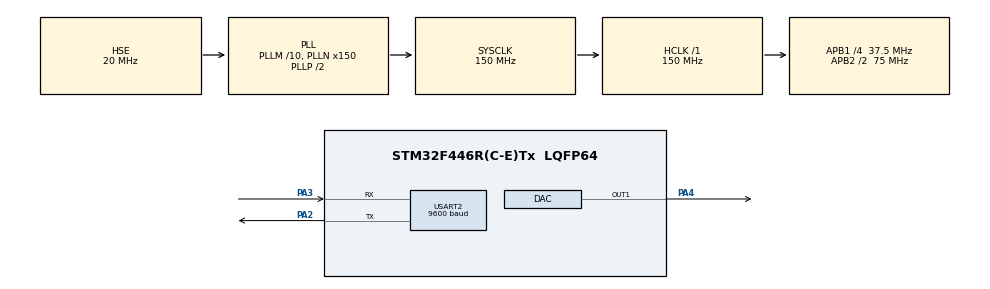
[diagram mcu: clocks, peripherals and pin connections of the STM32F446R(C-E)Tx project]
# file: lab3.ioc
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Mcu.Family=STM32F4
Mcu.Name=STM32F446R(C-E)Tx
Mcu.Package=LQFP64
NVIC.PriorityGroup=NVIC_PRIORITYGROUP_4
NVIC.TIM1_UP_TIM10_IRQn=true\:0\:0\:false\:false\:true\:true\:true\:true
NVIC.USART2_IRQn=true\:0\:0\:false\:false\:true\:true\:true\:true
PA2.Mode=Asynchronous
PA2.Signal=USART2_TX
PA3.Mode=Asynchronous
PA3.Signal=USART2_RX
PA4.Signal=COMP_DAC1_group
PH0-OSC_IN.Mode=HSE-External-Oscillator
PH0-OSC_IN.Signal=RCC_OSC_IN
PH1-OSC_OUT.Mode=HSE-External-Oscillator
PH1-OSC_OUT.Signal=RCC_OSC_OUT
ProjectManager.HeapSize=0x200
ProjectManager.StackSize=0x400
ProjectManager.TargetToolchain=STM32CubeIDE
RCC.AHBFreq_Value=150000000
RCC.APB1CLKDivider=RCC_HCLK_DIV4
RCC.APB1Freq_Value=37500000
RCC.APB1TimFreq_Value=75000000
RCC.APB2CLKDivider=RCC_HCLK_DIV2
RCC.APB2Freq_Value=75000000
RCC.APB2TimFreq_Value=150000000
RCC.CortexFreq_Value=150000000
RCC.HCLKFreq_Value=150000000
RCC.HSE_VALUE=20000000
RCC.PLLM=10
RCC.PLLN=150
RCC.PLLSourceVirtual=RCC_PLLSOURCE_HSE
RCC.SYSCLKFreq_VALUE=150000000
RCC.SYSCLKSource=RCC_SYSCLKSOURCE_PLLCLK
RCC.USBFreq_Value=150000000
RCC.VCOOutputFreq_Value=300000000
SH.COMP_DAC1_group.0=DAC_OUT1,DAC_OUT1
TIM1.Period=999
TIM1.Prescaler=149
TIM1.TIM_MasterOutputTrigger=TIM_TRGO_UPDATE
USART2.BaudRate=9600
USART2.VirtualMode=VM_ASYNC
VP_TIM1_VS_ClockSourceINT.Mode=Internal
board=custom

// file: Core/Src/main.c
/* USER CODE BEGIN Header */
/**
  ******************************************************************************
  * @file           : main.c
  * @brief          : Main program body
  ******************************************************************************
  * @attention
  *
  * Copyright (c) 2024 STMicroelectronics.
  * All rights reserved.
  *
  * This software is licensed under terms that can be found in the LICENSE file
  * in the root directory of this software component.
  * If no LICENSE file comes with this software, it is provided AS-IS.
  *
  ******************************************************************************
  */
/* USER CODE END Header */
#include "main.h"

/* USER CODE BEGIN Includes */
#include <math.h>
#include <string.h>
#include <stdio.h>
/* USER CODE END Includes */

/* USER CODE BEGIN PD */
#define SAMPLE_RATE 1000
#define VREF 3.3

#define UART_BUFFER_SIZE 5
/* USER CODE END PD */

DAC_HandleTypeDef hdac;

TIM_HandleTypeDef htim1;

UART_HandleTypeDef huart2;

/* USER CODE BEGIN PV */
float frequency = 30.0;
float amplitude_volts = 1.5;
float phase = 0.0;

volatile uint32_t dac_value;
volatile float dac_output_voltage;

uint8_t rx_buffer[UART_BUFFER_SIZE];
/* USER CODE END PV */

void SystemClock_Config(void);
static void MX_GPIO_Init(void);
static void MX_DAC_Init(void);
static void MX_TIM1_Init(void);
static void MX_USART2_UART_Init(void);
/* USER CODE BEGIN PFP */
void update_sine_wave(void);
uint32_t calculate_dac_value(float sine_voltage);
/* USER CODE END PFP */

int main(void)
{

  /* MCU Configuration--------------------------------------------------------*/

  /* Reset of all peripherals, Initializes the Flash interface and the Systick. */
  HAL_Init();

  /* Configure the system clock */
  SystemClock_Config();

  /* Initialize all configured peripherals */
  MX_GPIO_Init();
  MX_DAC_Init();
  MX_TIM1_Init();
  MX_USART2_UART_Init();
  /* USER CODE BEGIN 2 */
  HAL_UART_Receive_IT(&huart2, rx_buffer, UART_BUFFER_SIZE);
  HAL_DAC_Start(&hdac, DAC_CHANNEL_1);

  /* USER CODE END 2 */

  /* Infinite loop */
  while (1)
  {

  }
}

void SystemClock_Config(void)
{
  RCC_OscInitTypeDef RCC_OscInitStruct = {0};
  RCC_ClkInitTypeDef RCC_ClkInitStruct = {0};

  /** Configure the main internal regulator output voltage
  */
  __HAL_RCC_PWR_CLK_ENABLE();
  __HAL_PWR_VOLTAGESCALING_CONFIG(PWR_REGULATOR_VOLTAGE_SCALE1);

  /** Initializes the RCC Oscillators according to the specified parameters
  * in the RCC_OscInitTypeDef structure.
  */
  RCC_OscInitStruct.OscillatorType = RCC_OSCILLATORTYPE_HSE;
  RCC_OscInitStruct.HSEState = RCC_HSE_ON;
  RCC_OscInitStruct.PLL.PLLState = RCC_PLL_ON;
  RCC_OscInitStruct.PLL.PLLSource = RCC_PLLSOURCE_HSE;
  RCC_OscInitStruct.PLL.PLLM = 10;
  RCC_OscInitStruct.PLL.PLLN = 150;
  RCC_OscInitStruct.PLL.PLLP = RCC_PLLP_DIV2;
  RCC_OscInitStruct.PLL.PLLQ = 2;
  RCC_OscInitStruct.PLL.PLLR = 2;
  if (HAL_RCC_OscConfig(&RCC_OscInitStruct) != HAL_OK)
  {
    Error_Handler();
  }

  /** Initializes the CPU, AHB and APB buses clocks
  */
  RCC_ClkInitStruct.ClockType = RCC_CLOCKTYPE_HCLK|RCC_CLOCKTYPE_SYSCLK
                              |RCC_CLOCKTYPE_PCLK1|RCC_CLOCKTYPE_PCLK2;
  RCC_ClkInitStruct.SYSCLKSource = RCC_SYSCLKSOURCE_PLLCLK;
  RCC_ClkInitStruct.AHBCLKDivider = RCC_SYSCLK_DIV1;
  RCC_ClkInitStruct.APB1CLKDivider = RCC_HCLK_DIV4;
  RCC_ClkInitStruct.APB2CLKDivider = RCC_HCLK_DIV2;

  if (HAL_RCC_ClockConfig(&RCC_ClkInitStruct, FLASH_LATENCY_4) != HAL_OK)
  {
    Error_Handler();
  }
}

static void MX_DAC_Init(void)
{

  DAC_ChannelConfTypeDef sConfig = {0};

  /** DAC Initialization
  */
  hdac.Instance = DAC;
  if (HAL_DAC_Init(&hdac) != HAL_OK)
  {
    Error_Handler();
  }

  /** DAC channel OUT1 config
  */
  sConfig.DAC_Trigger = DAC_TRIGGER_NONE;
  sConfig.DAC_OutputBuffer = DAC_OUTPUTBUFFER_ENABLE;
  if (HAL_DAC_ConfigChannel(&hdac, &sConfig, DAC_CHANNEL_1) != HAL_OK)
  {
    Error_Handler();
  }

}

static void MX_TIM1_Init(void)
{

  TIM_ClockConfigTypeDef sClockSourceConfig = {0};
  TIM_MasterConfigTypeDef sMasterConfig = {0};

  htim1.Instance = TIM1;
  htim1.Init.Prescaler = 149;
  htim1.Init.CounterMode = TIM_COUNTERMODE_UP;
  htim1.Init.Period = 999;
  htim1.Init.ClockDivision = TIM_CLOCKDIVISION_DIV1;
  htim1.Init.RepetitionCounter = 0;
  htim1.Init.AutoReloadPreload = TIM_AUTORELOAD_PRELOAD_DISABLE;
  if (HAL_TIM_Base_Init(&htim1) != HAL_OK)
  {
    Error_Handler();
  }
  sClockSourceConfig.ClockSource = TIM_CLOCKSOURCE_INTERNAL;
  if (HAL_TIM_ConfigClockSource(&htim1, &sClockSourceConfig) != HAL_OK)
  {
    Error_Handler();
  }
  sMasterConfig.MasterOutputTrigger = TIM_TRGO_UPDATE;
  sMasterConfig.MasterSlaveMode = TIM_MASTERSLAVEMODE_DISABLE;
  if (HAL_TIMEx_MasterConfigSynchronization(&htim1, &sMasterConfig) != HAL_OK)
  {
    Error_Handler();
  }
  /* USER CODE BEGIN TIM1_Init 2 */
	HAL_NVIC_SetPriority(TIM1_UP_TIM10_IRQn, 0, 0);
	HAL_NVIC_EnableIRQ(TIM1_UP_TIM10_IRQn);
	HAL_TIM_Base_Start_IT(&htim1);
  /* USER CODE END TIM1_Init 2 */

}

static void MX_USART2_UART_Init(void)
{

  huart2.Instance = USART2;
  huart2.Init.BaudRate = 9600;
  huart2.Init.WordLength = UART_WORDLENGTH_8B;
  huart2.Init.StopBits = UART_STOPBITS_1;
  huart2.Init.Parity = UART_PARITY_NONE;
  huart2.Init.Mode = UART_MODE_TX_RX;
  huart2.Init.HwFlowCtl = UART_HWCONTROL_NONE;
  huart2.Init.OverSampling = UART_OVERSAMPLING_16;
  if (HAL_UART_Init(&huart2) != HAL_OK)
  {
    Error_Handler();
  }

}

static void MX_GPIO_Init(void)
{

  /* GPIO Ports Clock Enable */
  __HAL_RCC_GPIOH_CLK_ENABLE();
  __HAL_RCC_GPIOA_CLK_ENABLE();

}

/* USER CODE BEGIN 4 */
uint32_t calculate_dac_value(float sine_voltage) {
    return (uint32_t)((sine_voltage / VREF) * 4095);
}

void update_sine_wave(void) {
    float delta_theta = 2.0f * M_PI * frequency / SAMPLE_RATE;
    phase += delta_theta;
    if (phase > 2.0f * M_PI) {
        phase -= 2.0f * M_PI;
    }

    dac_output_voltage = VREF / 2 + amplitude_volts * sin(phase);

    dac_value = calculate_dac_value(dac_output_voltage);
    HAL_DAC_SetValue(&hdac, DAC_CHANNEL_1, DAC_ALIGN_12B_R, dac_value);
}

void Process_Command(uint8_t *cmd) {
    char command_type = cmd[0];
    float value = 0.0;

    if (cmd[2] == '.' && command_type == 'A') {
        int integer_part = (cmd[1] - '0');
        int decimal_part = ((cmd[3] - '0') * 10) + (cmd[4] - '0');
        value = integer_part + (decimal_part / 100.0);

        if (value >= 1 && value <= VREF) {
            amplitude_volts = value / 2;
        }
    }
    else if (cmd[3] == '.' && command_type == 'F') {
        int integer_part = ((cmd[1] - '0') * 10) + (cmd[2] - '0');
        int decimal_part = (cmd[4] - '0');
        value = integer_part + (decimal_part / 10.0);

        if (value >= 5 && value <= 35) {
            frequency = value;
        }
    }
}

void HAL_UART_RxCpltCallback(UART_HandleTypeDef *huart) {
    if (huart->Instance == USART2) {
        Process_Command(rx_buffer);
        HAL_UART_Receive_IT(&huart2, rx_buffer, UART_BUFFER_SIZE);
    }
}

void HAL_TIM_PeriodElapsedCallback(TIM_HandleTypeDef *htim) {
    if (htim->Instance == TIM1) {
        update_sine_wave();
    }
}
/* USER CODE END 4 */

void Error_Handler(void)
{
  __disable_irq();
  while (1)
  {
  }
}
